# CY8C5868AXI_LP032 register map
File version: 0.1
CY8C58LP
Registers are 8-bit, read-write, no defined reset value unless marked. A register's access mark holds for its fields unless they carry their own. Offsets are from the block's base; lines under a group give offsets from that group; [hi:lo] are bit positions; {n}, {i} and the like mark numbered series; 'fields as' and 'values as' point back to an identical list; <NAME> marks a mode.

## Memory map
0x00000000 RTC_1 — RTC
0x00000000 DEB_UART — UART
0x00000000 KeisokuTimer
0x00000000 WDT_detect_com_err
0x00000000 Timer_PWM
0x00000000 Timer_cycle
0x00000000 USBUART_1 — USBFS
0x00000000 VDAC8_1
0x00000000 ADC_SAR_1 — SAR ADC
0x00000000 Timer_sub_cycle
0x40006476 motor_en_reg
0x40006478 motor_contl_reg_1
0x4000647A motor_contl_reg_0
0x4000656B BMP_SW
0x40006575 SS0_B

## BMP_SW
Base 0x4000656B
0x00 BMP_SW_STATUS_REG
0x20 BMP_SW_MASK_REG
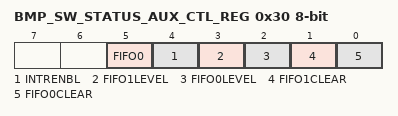
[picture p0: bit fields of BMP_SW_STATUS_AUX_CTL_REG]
0x30 BMP_SW_STATUS_AUX_CTL_REG
  [5] FIFO0 — FIFO0 clear
    1=ENABLED (Enable counter); 0=DISABLED (Disable counter)
  [4] INTRENBL — Enables or disables the Interrupt
    1=ENABLED (Interrupt enabled); 0=DISABLED (Interrupt disabled)
  [3] FIFO1LEVEL — FIFO level
    1=ENABLED (FIFO LVL: input mode: FIFO at least 1/2 empty; output mode: FIFO at least 1/2 full); 0=DISABLED (FIFO LVL: input mode: FIFO not full; output mode: FIFO not empty)
  [2] FIFO0LEVEL — FIFO level
    values as FIFO1LEVEL
  [1] FIFO1CLEAR — FIFO clear
    1=ENABLED (Clear FIFO state); 0=DISABLED (Normal FIFO operation)
  [0] FIFO0CLEAR — FIFO clear
    values as FIFO1CLEAR

## motor_contl_reg_1
Base 0x40006478
0x00 motor_contl_reg_1_CONTROL_REG

## motor_contl_reg_0
Base 0x4000647A
Registers as motor_contl_reg_1 (with motor_contl_reg_1 read as motor_contl_reg_0).

## motor_en_reg
Base 0x40006476
Registers as motor_contl_reg_1 (with motor_contl_reg_1 read as motor_en_reg).

## SS0_B
Base 0x40006575
Registers as motor_contl_reg_1 (with motor_contl_reg_1 read as SS0_B).

## RTC_1 — RTC
Base 0x00000000
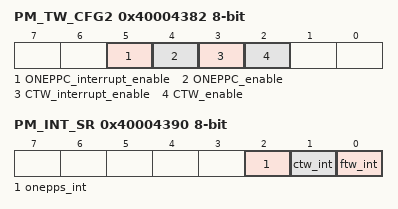
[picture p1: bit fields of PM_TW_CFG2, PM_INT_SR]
0x40004382 PM_TW_CFG2 — Power timers enable and interrupt enable configuration register
  [5] ONEPPC_interrupt_enable — When set and one pulse-per-second is enabled, an interrupt is issued when the pulse occurs
    1=Enabled (The ONEPPC interrupt is issued. Only if ONEPPC is enabled.); 0=Disabled (No ONEPPC interrupt is issued.)
  [4] ONEPPC_enable
    1=Enabled (The ONEPPC is enabled.); 0=Disabled (The ONEPPC is disabled.)
  [3] CTW_interrupt_enable — An interrupt issue when the CTW reaches the selected interval
    1=Enabled (The CTW interrupt is issued. Only if CTW is enabled.); 0=Disabled (No CTW interrupt is issued.)
  [2] CTW_enable
    1=Enabled (The CTW is enabled.); 0=Disabled (The CTW is disabled.)
0x40004390 PM_INT_SR — Power Manager Interrupt Status Register
  [2] onepps_int — When set, a onepps event has occured.
  [1] ctw_int — When set, a limited active ready event has occured
  [0] ftw_int — When set, a fast timewheel event has occured

## DEB_UART — UART
Base 0x00000000
0x4000642B RX_DEB_UART_RX_ADDRESS1 — RX Address1 Register
0x4000643B RX_DEB_UART_RX_ADDRESS2 — RX Address2 Register
0x4000644B RX_DEB_UART_RX_DATA — RX Data Register
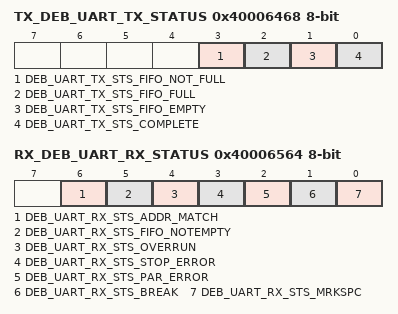
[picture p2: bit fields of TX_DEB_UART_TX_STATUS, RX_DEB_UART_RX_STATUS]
0x40006468 TX_DEB_UART_TX_STATUS — TX status register
  [3] DEB_UART_TX_STS_FIFO_NOT_FULL ro, [2] DEB_UART_TX_STS_FIFO_FULL ro, [1] DEB_UART_TX_STS_FIFO_EMPTY ro, [0] DEB_UART_TX_STS_COMPLETE ro
0x4000654B TX_DEB_UART_TX_DATA — TX Data Register
0x40006564 RX_DEB_UART_RX_STATUS — RX status register
  [6] DEB_UART_RX_STS_ADDR_MATCH ro, [5] DEB_UART_RX_STS_FIFO_NOTEMPTY ro, [4] DEB_UART_RX_STS_OVERRUN ro, [3] DEB_UART_RX_STS_STOP_ERROR ro, [2] DEB_UART_RX_STS_PAR_ERROR ro, [1] DEB_UART_RX_STS_BREAK ro, [0] DEB_UART_RX_STS_MRKSPC ro

## KeisokuTimer
Base 0x00000000
0x400043A3 KeisokuTimer_GLOBAL_ENABLE — PM.ACT.CFG
  [3:0] en_timer — Enable timer/counters.
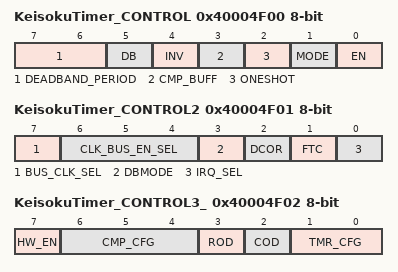
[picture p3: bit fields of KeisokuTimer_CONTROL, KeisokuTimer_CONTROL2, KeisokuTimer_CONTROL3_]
0x40004F00 KeisokuTimer_CONTROL — TMRx.CFG0
  [7:6] DEADBAND_PERIOD
  [5] DB — Deadband mode--Deadband phases phi1 and phi2 are outputted on CMP and TC output pins respectively.
    0=Timer (CMP and TC are output.); 1=Deadband (PHI1 (instead of CMP) and PHI2 (instead of TC) are output.)
  [4] INV — Invert sense of TIMEREN signal
  [3] CMP_BUFF — Buffer compare register. Compare register updates only on timer terminal count.
  [2] ONESHOT — Timer stops upon reaching stop condition defined by TMR_CFG bits. Can be restarted by asserting TIMER RESET or disabling and re-enabling block.
  [1] MODE — Mode. (0 = Timer; 1 = Comparator)
    0=Timer mode. CNT/CMP register holds timer count value.; 1=Comparator mode. CNT/CMP register holds comparator threshold value.
  [0] EN — Enables timer/comparator.
0x40004F01 KeisokuTimer_CONTROL2 — TMRx.CFG1
  [7] BUS_CLK_SEL — Bus Clock selection.
  [6:4] CLK_BUS_EN_SEL — Digital Global Clock selection.
  [3] DBMODE — Deadband mode (asynchronous/synchronous). CMP output pin is also affected when not in deadband mode (CFG0.DEADBAND).
  [2] DCOR — Disable Clear on Read (DCOR) of Status Register SR0.
  [1] FTC — First Terminal Count (FTC). Setting this bit forces a single pulse on the TC pin when first enabled.
    0=Disable_FTC (Disable the single cycle pulse, which signifies the timer is starting.); 1=Enable_FTC (Enable the single cycle pulse, which signifies the timer is starting.)
  [0] IRQ_SEL — Irq selection. (0 = raw interrupts; 1 = status register interrupts)
0x40004F02 KeisokuTimer_CONTROL3_ — TMRx.CFG2
  [7] HW_EN — When set Timer Enable controls counting.
  [6:4] CMP_CFG — Comparator configurations
    0=Equal (Compare Equal); 1=Less_than (Compare Less Than); 2=Less_than_or_equal (Compare Less Than or Equal .); 3=Greater (Compare Greater Than .); 4=Greater_than_or_equal (Compare Greater Than or Equal)
  [3] ROD — Reset On Disable (ROD). Resets internal state of output logic
  [2] COD — Clear On Disable (COD). Clears or gates outputs to zero.
  [1:0] TMR_CFG — Timer configuration (MODE = 0): 000 = Continuous; 001 = Pulsewidth; 010 = Period; 011 = Stop on IRQ
    0=Continuous (Timer runs while EN bit of CFG0 register is set to '1'.); 1=Pulsewidth (Timer runs from positive to negative edge of TIMEREN.); 2=Period (Timer runs from positive to positive edge of TIMEREN.); 3=Irq (Timer runs until IRQ.)
0x40004F04 KeisokuTimer_PERIOD 16-bit — TMRx.PER0 - Assigned Period
0x40004F06 KeisokuTimer_COUNTER 16-bit — TMRx.CNT_CMP0 - Current Down Counter Value
